# STM32WLE4C8U6 register map
File version: 1.0
STM32WLE4C8U6,STM32WLE4CBU6,STM32WLE4CCU6,STM32WLE4CCU7,STM32WLE4J8I6,STM32WLE4JBI6,STM32WLE4JCI6,STM32WLE4JCI7,STM32WLE5C8U6,STM32WLE5CBU6,STM32WLE5CCU6,STM32WLE5CCU7,STM32WLE5J8I6,STM32WLE5JBI6,STM32WLE5JCI6,STM32WLE5JCI7
Registers are 32-bit, access not given, reset 0x0 unless marked. A register's access mark holds for its fields unless they carry their own. Offsets are from the block's base; lines under a group give offsets from that group; [hi:lo] are bit positions; {n}, {i} and the like mark numbered series; 'fields as' and 'values as' point back to an identical list; <NAME> marks a mode.

## Memory map
0x1FFF7800 FLASH
0x40000000 TIM2
0x40002800 RTC
0x40002C00 WWDG
0x40003000 IWDG
0x40003800 SPI2
0x40004400 USART2
0x40005400 I2C1
0x40005800 I2C2
0x40005C00 I2C3
0x40007400 DAC
0x40007C00 LPTIM1
0x40008000 LPUART1
0x40009400 LPTIM2
0x40009800 LPTIM3
0x4000B000 TAMP
0x40010000 SYSCFG
0x40010030 VREFBUF
0x40010100 SYSCFG
0x40010200 COMP
0x40012400 ADC
0x40012C00 TIM1
0x40013000 SPI1
0x40013800 USART1
0x40014400 TIM16
0x40014800 TIM17
0x40020000 DMA1
0x40020400 DMA2
0x40020800 DMAMUX1
0x40023000 CRC
0x48000000 GPIO
0x48000400 GPIO
0x48000800 GPIO
0x48001C00 GPIO
0x58000000 RCC
0x58000400 PWR
0x58000800 EXTI
0x58001000 TRNG
0x58001400 HSEM
0x58001800 AES
0x58002000 PKA
0x58002400 PKARAM
0x58003400 PKA
0x58004000 FLASH
0x58010000 SUBGHZSPI

## FLASH
Base 0x1FFF7800
Same registers: FLASH 0x58004000, FLASH 0x58004000
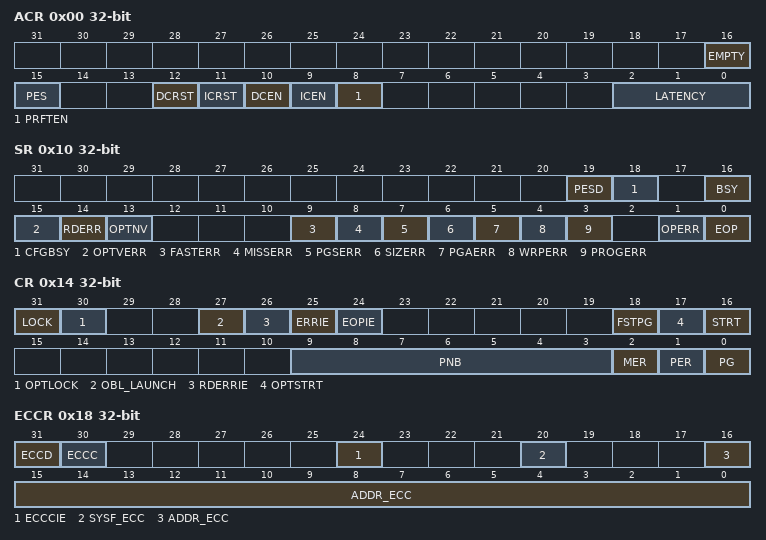
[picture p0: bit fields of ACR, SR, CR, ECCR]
0x00 ACR
  [16] EMPTY, [15] PES, [12] DCRST, [11] ICRST, [10] DCEN, [9] ICEN, [8] PRFTEN, [2:0] LATENCY
0x08 KEYR
0x0C OPTKEYR
  [31:0] OPTKEY
0x10 SR
  [19] PESD, [18] CFGBSY, [16] BSY, [15] OPTVERR, [14] RDERR, [13] OPTNV, [9] FASTERR, [8] MISSERR, [7] PGSERR, [6] SIZERR, [5] PGAERR, [4] WRPERR, [3] PROGERR, [1] OPERR, [0] EOP
0x14 CR
  [31] LOCK, [30] OPTLOCK, [27] OBL_LAUNCH, [26] RDERRIE, [25] ERRIE, [24] EOPIE, [18] FSTPG, [17] OPTSTRT, [16] STRT, [9:3] PNB, [2] MER, [1] PER, [0] PG
0x18 ECCR
  [31] ECCD, [30] ECCC, [24] ECCCIE, [20] SYSF_ECC, [16:0] ADDR_ECC
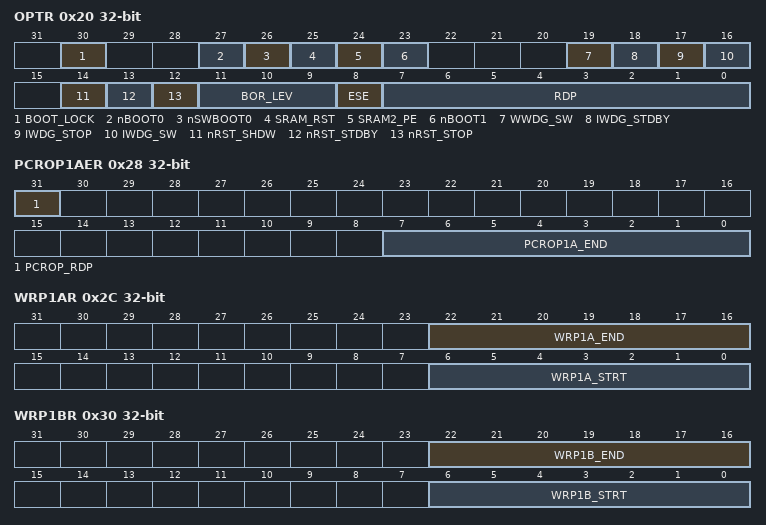
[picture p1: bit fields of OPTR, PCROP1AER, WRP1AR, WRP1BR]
0x20 OPTR
  [30] BOOT_LOCK, [27] nBOOT0, [26] nSWBOOT0, [25] SRAM_RST, [24] SRAM2_PE, [23] nBOOT1, [19] WWDG_SW, [18] IWDG_STDBY, [17] IWDG_STOP, [16] IWDG_SW, [14] nRST_SHDW, [13] nRST_STDBY, [12] nRST_STOP, [11:9] BOR_LEV, [8] ESE, [7:0] RDP
0x24 PCROP1ASR
  [7:0] PCROP1A_STRT
0x28 PCROP1AER
  [31] PCROP_RDP, [7:0] PCROP1A_END
0x2C WRP1AR
  [22:16] WRP1A_END, [6:0] WRP1A_STRT
0x30 WRP1BR
  [22:16] WRP1B_END, [6:0] WRP1B_STRT
0x34 PCROP1BSR
  [7:0] PCROP1B_STRT
0x38 PCROP1BER
  [7:0] PCROP1B_END

## TIM2
Base 0x40000000
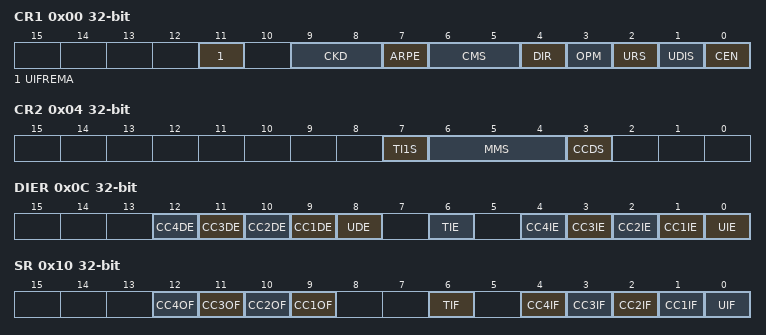
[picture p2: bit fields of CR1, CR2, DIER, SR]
0x00 CR1
  [11] UIFREMA, [9:8] CKD, [7] ARPE, [6:5] CMS, [4] DIR, [3] OPM, [2] URS, [1] UDIS, [0] CEN
0x04 CR2
  [7] TI1S, [6:4] MMS, [3] CCDS
0x08 SMCR
  [15] ETP, [14] ECE, [13:12] ETPS, [11:8] ETF, [7] MSM, [21:4] TS, [16:0] SMS
0x0C DIER
  [n+8] CC{n}DE (n=1..4), [8] UDE, [6] TIE, [n] CC{n}IE (n=1..4), [0] UIE
0x10 SR
  [n+8] CC{n}OF (n=1..4), [6] TIF, [n] CC{n}IF (n=1..4), [0] UIF
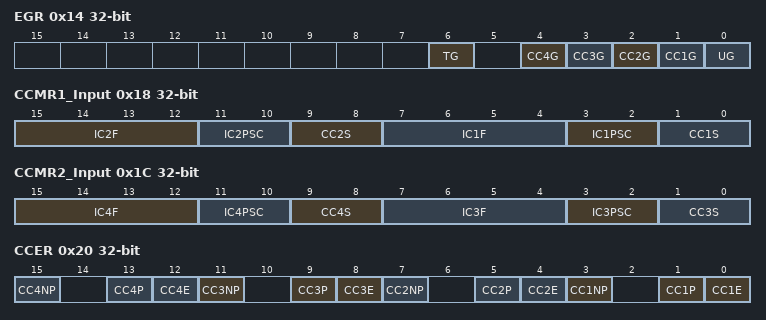
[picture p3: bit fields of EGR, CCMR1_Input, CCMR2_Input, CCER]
0x14 EGR
  [6] TG, [n] CC{n}G (n=1..4), [0] UG
0x18 CCMR1_Output
  [15] OC2CE, [24:12] OC2M, [11] OC2PE, [10] OC2FE, [9:8] CC2S, [7] OC1CE, [16:4] OC1M, [3] OC1PE, [2] OC1FE, [1:0] CC1S
0x18 CCMR1_Input
  [15:12] IC2F, [11:10] IC2PSC, [9:8] CC2S, [7:4] IC1F, [3:2] IC1PSC, [1:0] CC1S
0x1C CCMR2_Output
  [15] O24CE, [24:12] OC4M, [11] OC4PE, [10] OC4FE, [9:8] CC4S, [7] OC3CE, [16:4] OC3M, [3] OC3PE, [2] OC3FE, [1:0] CC3S
0x1C CCMR2_Input
  [15:12] IC4F, [11:10] IC4PSC, [9:8] CC4S, [7:4] IC3F, [3:2] IC3PSC, [1:0] CC3S
0x20 CCER
  [4n-1] CC{n}NP (n=1..4), [4n-3] CC{n}P (n=1..4), [4n-4] CC{n}E (n=1..4)
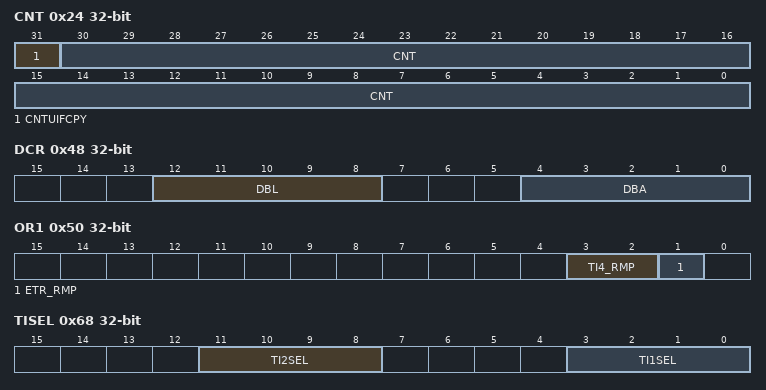
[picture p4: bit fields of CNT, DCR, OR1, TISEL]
0x24 CNT
  [31] CNTUIFCPY, [30:0] CNT
0x28 PSC
  [15:0] PSC
0x2C ARR
{0x30+4i} CCR{i} (i=1..4)
0x48 DCR
  [12:8] DBL, [4:0] DBA
0x4C DMAR
  [15:0] DMAB
0x50 OR1
  [3:2] TI4_RMP, [1] ETR_RMP
0x60 AF1
  [17:14] ETRSEL
0x68 TISEL
  [11:8] TI2SEL, [3:0] TI1SEL

## RTC
Base 0x40002800
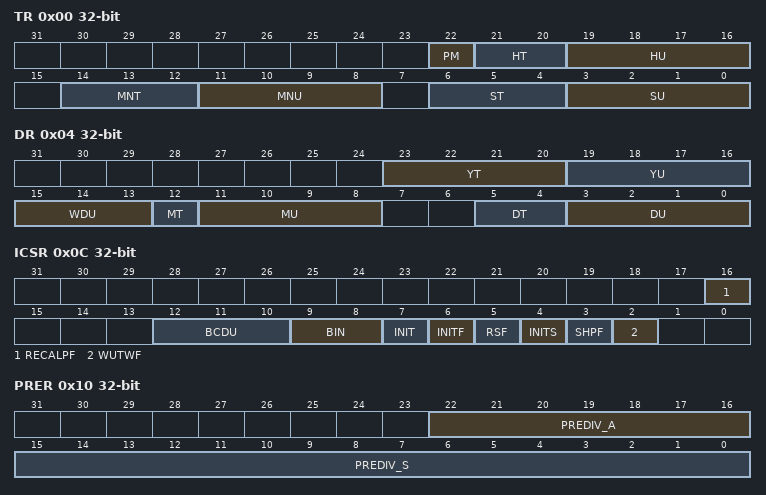
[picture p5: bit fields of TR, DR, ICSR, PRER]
0x00 TR
  [22] PM, [21:20] HT, [19:16] HU, [14:12] MNT, [11:8] MNU, [6:4] ST, [3:0] SU
0x04 DR
  [23:20] YT, [19:16] YU, [15:13] WDU, [12] MT, [11:8] MU, [5:4] DT, [3:0] DU
0x08 SSR
  [31:0] SS
0x0C ICSR
  [16] RECALPF, [12:10] BCDU, [9:8] BIN, [7] INIT, [6] INITF, [5] RSF, [4] INITS, [3] SHPF, [2] WUTWF
0x10 PRER
  [22:16] PREDIV_A, [15:0] PREDIV_S
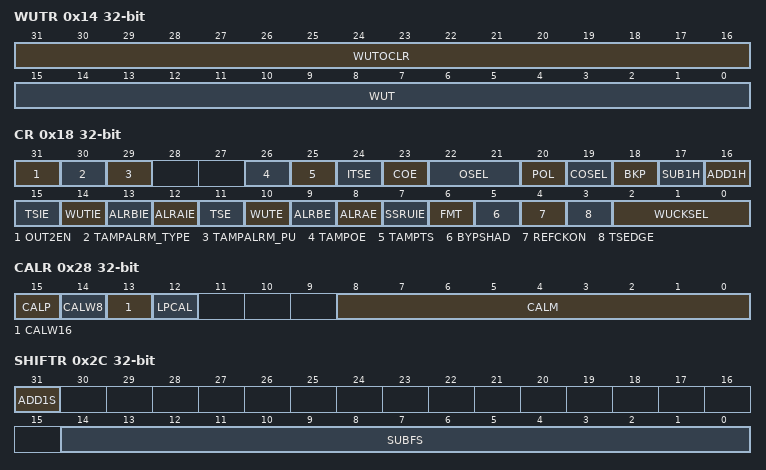
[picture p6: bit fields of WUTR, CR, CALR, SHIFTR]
0x14 WUTR
  [31:16] WUTOCLR, [15:0] WUT
0x18 CR
  [31] OUT2EN, [30] TAMPALRM_TYPE, [29] TAMPALRM_PU, [26] TAMPOE, [25] TAMPTS, [24] ITSE, [23] COE, [22:21] OSEL, [20] POL, [19] COSEL, [18] BKP, [17] SUB1H, [16] ADD1H, [15] TSIE, [14] WUTIE, [13] ALRBIE, [12] ALRAIE, [11] TSE, [10] WUTE, [9] ALRBE, [8] ALRAE, [7] SSRUIE, [6] FMT, [5] BYPSHAD, [4] REFCKON, [3] TSEDGE, [2:0] WUCKSEL
0x24 WPR
  [7:0] KEY
0x28 CALR
  [15] CALP, [14] CALW8, [13] CALW16, [12] LPCAL, [8:0] CALM
0x2C SHIFTR
  [31] ADD1S, [14:0] SUBFS
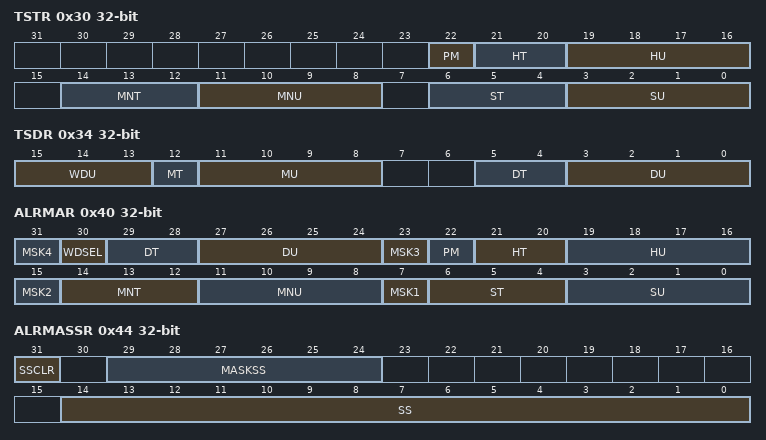
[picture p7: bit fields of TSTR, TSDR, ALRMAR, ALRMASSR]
0x30 TSTR
  fields as TR
0x34 TSDR
  [15:13] WDU, [12] MT, [11:8] MU, [5:4] DT, [3:0] DU
0x38 TSSSR
  [31:0] SS
0x40 ALRMAR
  [8n-1] MSK{n} (n=1..4), [30] WDSEL, [29:28] DT, [27:24] DU, [22] PM, [21:20] HT, [19:16] HU, [14:12] MNT, [11:8] MNU, [6:4] ST, [3:0] SU
0x44 ALRMASSR
  [31] SSCLR, [29:24] MASKSS, [14:0] SS
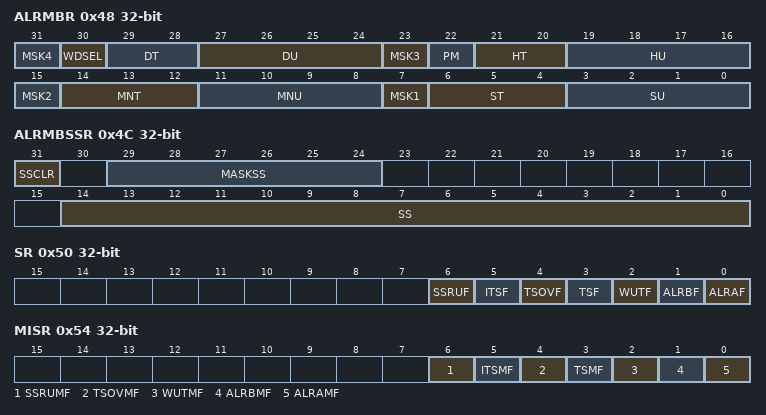
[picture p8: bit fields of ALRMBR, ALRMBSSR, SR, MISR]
0x48 ALRMBR
  fields as ALRMAR
0x4C ALRMBSSR
  [31] SSCLR, [29:24] MASKSS, [14:0] SS
0x50 SR
  [6] SSRUF, [5] ITSF, [4] TSOVF, [3] TSF, [2] WUTF, [1] ALRBF, [0] ALRAF
0x54 MISR
  [6] SSRUMF, [5] ITSMF, [4] TSOVMF, [3] TSMF, [2] WUTMF, [1] ALRBMF, [0] ALRAMF
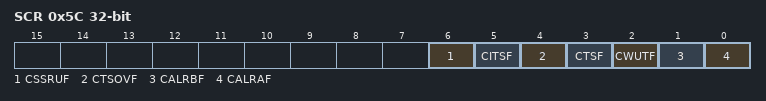
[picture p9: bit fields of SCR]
0x5C SCR
  [6] CSSRUF, [5] CITSF, [4] CTSOVF, [3] CTSF, [2] CWUTF, [1] CALRBF, [0] CALRAF
0x70 ALRABINR
  [31:0] SS
0x74 ALRBBINR
  [31:0] SS
